AUTOSAR XML (schema 4-0-3)
package /WdgM/CompuMethods
  compu method WdgM_ModeIdTypeValues: 0=WDGM_WDGMMODE0 (WdgMMode0), 1=WDGM_WDGMMODE1 (WdgMMode1)
  compu method WdgM_SupervisedEntityIdTypeValues: 300=WDGM_SE_INIT (SE_Init), 400=WDGM_SE_WDGMTEST (SE_WdgMTest), 500=WDGM_SE_WDGMELS_01 (SE_WdgMELS_01), 600=WDGM_SE_WDGMELS_02 (SE_WdgMELS_02)
  compu method WdgM_CheckpointIdTypeValues: 0=WDGM_SE_INIT_CP_INIT_AS0 (SE_Init_CP_Init_AS0), 1=WDGM_SE_INIT_CP_INIT_ILS_0 (SE_Init_CP_Init_ILS_0), 2=WDGM_SE_INIT_CP_INIT_ILS_1 (SE_Init_CP_Init_ILS_1), 0=WDGM_SE_WDGMTEST_CP_WDGMTEST_AS0 (SE_WdgMTest_CP_WdgMTest_AS0), 1=WDGM_SE_WDGMTEST_CP_WDGMTEST_ILS_0 (SE_WdgMTest_CP_WdgMTest_ILS_0), 2=WDGM_SE_WDGMTEST_CP_WDGMTEST_ILS_1 (SE_WdgMTest_CP_WdgMTest_ILS_1), 3=WDGM_SE_WDGMTEST_CP_WDGMTEST_ILS_2 (SE_WdgMTest_CP_WdgMTest_ILS_2), 4=WDGM_SE_WDGMTEST_CP_WDGMTEST_DS0 (SE_WdgMTest_CP_WdgMTest_DS0), 5=WDGM_SE_WDGMTEST_CP_WDGMTEST_DS1 (SE_WdgMTest_CP_WdgMTest_DS1), 0=WDGM_SE_WDGMELS_01_CP_ELS_01_01 (SE_WdgMELS_01_CP_ELS_01_01), 1=WDGM_SE_WDGMELS_01_CP_ELS_01_02 (SE_WdgMELS_01_CP_ELS_01_02), 2=WDGM_SE_WDGMELS_01_CP_ELS_01_ILS_01 (SE_WdgMELS_01_CP_ELS_01_ILS_01), 3=WDGM_SE_WDGMELS_01_CP_ELS_01_ILS_02 (SE_WdgMELS_01_CP_ELS_01_ILS_02), 0=WDGM_SE_WDGMELS_02_CP_ELS_02_01 (SE_WdgMELS_02_CP_ELS_02_01), 1=WDGM_SE_WDGMELS_02_CP_ELS_02_02 (SE_WdgMELS_02_CP_ELS_02_02), 2=WDGM_SE_WDGMELS_02_CP_ELS_02_ILS_01 (SE_WdgMELS_02_CP_ELS_02_ILS_01), 3=WDGM_SE_WDGMELS_02_CP_ELS_02_ILS_02 (SE_WdgMELS_02_CP_ELS_02_ILS_02)
package /WdgM/ServiceSwComponentTypes
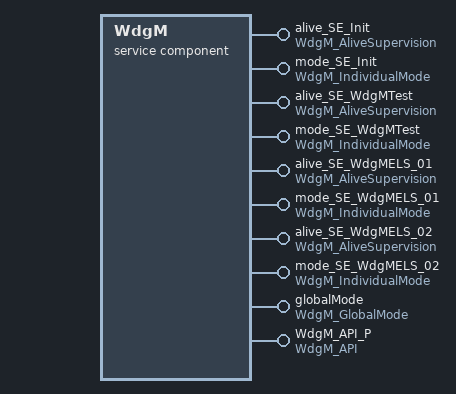
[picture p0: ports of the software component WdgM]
  service sw component type WdgM
    10 x provide port:
      alive_SE_Init: provided-com-specs=[{operation=CheckpointReached, queue-length=1}, {operation=UpdateAliveCounter, queue-length=1}], provided-interface=WdgM_AliveSupervision  # alive_SE_Init is a P Port for supervised entity 'SE_Init'
      mode_SE_Init: mode-switch-sender-com-spec{enhanced-mode-api=false, mode-group=currentMode, queue-length=1}, provided-interface=WdgM_IndividualMode  # mode_SE_Init is a P Port for supervised entity 'SE_Init'
      alive_SE_WdgMTest: provided-com-specs=[{operation=CheckpointReached, queue-length=1}, {operation=UpdateAliveCounter, queue-length=1}], provided-interface=WdgM_AliveSupervision  # alive_SE_WdgMTest is a P Port for supervised entity 'SE_WdgMTest'
      mode_SE_WdgMTest: mode-switch-sender-com-spec{enhanced-mode-api=false, mode-group=currentMode, queue-length=1}, provided-interface=WdgM_IndividualMode  # mode_SE_WdgMTest is a P Port for supervised entity 'SE_WdgMTest'
      alive_SE_WdgMELS_01: provided-com-specs=[{operation=CheckpointReached, queue-length=1}, {operation=UpdateAliveCounter, queue-length=1}], provided-interface=WdgM_AliveSupervision  # alive_SE_WdgMELS_01 is a P Port for supervised entity 'SE_WdgMELS_01'
      mode_SE_WdgMELS_01: mode-switch-sender-com-spec{enhanced-mode-api=false, mode-group=currentMode, queue-length=1}, provided-interface=WdgM_IndividualMode  # mode_SE_WdgMELS_01 is a P Port for supervised entity 'SE_WdgMELS_01'
      alive_SE_WdgMELS_02: provided-com-specs=[{operation=CheckpointReached, queue-length=1}, {operation=UpdateAliveCounter, queue-length=1}], provided-interface=WdgM_AliveSupervision  # alive_SE_WdgMELS_02 is a P Port for supervised entity 'SE_WdgMELS_02'
      mode_SE_WdgMELS_02: mode-switch-sender-com-spec{enhanced-mode-api=false, mode-group=currentMode, queue-length=1}, provided-interface=WdgM_IndividualMode  # mode_SE_WdgMELS_02 is a P Port for supervised entity 'SE_WdgMELS_02'
      globalMode: mode-switch-sender-com-spec{enhanced-mode-api=false, mode-group=currentMode, queue-length=1}, provided-interface=WdgM_GlobalMode  # short_name is a P Port for supervised entity 'sesn'
      WdgM_API_P: provided-interface=WdgM_API  # short_name is a P Port for supervised entity 'sesn'
        provided-com-specs:
          operation=SetMode, queue-length=1
          operation=GetMode, queue-length=1
          operation=GetLocalStatus, queue-length=1
          operation=GetGlobalStatus, queue-length=1
          operation=PerformReset, queue-length=1
          operation=GetFirstExpiredSEID, queue-length=1
    behavior WdgMInternalBehavior: data-type-mapping=WdgM_Mode, handle-termination-and-restart=NO-SUPPORT
      14 x operation invoked event:
        OperationInvokedEvent_alive_SE_Init_CheckpointReached: start-on-event=CheckpointReached, operation=alive_SE_Init.CheckpointReached
        OperationInvokedEvent_alive_SE_Init_UpdateAliveCounter: start-on-event=UpdateAliveCounter, operation=alive_SE_Init.UpdateAliveCounter
        OperationInvokedEvent_alive_SE_WdgMTest_CheckpointReached: start-on-event=CheckpointReached, operation=alive_SE_WdgMTest.CheckpointReached
        OperationInvokedEvent_alive_SE_WdgMTest_UpdateAliveCounter: start-on-event=UpdateAliveCounter, operation=alive_SE_WdgMTest.UpdateAliveCounter
        OperationInvokedEvent_alive_SE_WdgMELS_01_CheckpointReached: start-on-event=CheckpointReached, operation=alive_SE_WdgMELS_01.CheckpointReached
        OperationInvokedEvent_alive_SE_WdgMELS_01_UpdateAliveCounter: start-on-event=UpdateAliveCounter, operation=alive_SE_WdgMELS_01.UpdateAliveCounter
        OperationInvokedEvent_alive_SE_WdgMELS_02_CheckpointReached: start-on-event=CheckpointReached, operation=alive_SE_WdgMELS_02.CheckpointReached
        OperationInvokedEvent_alive_SE_WdgMELS_02_UpdateAliveCounter: start-on-event=UpdateAliveCounter, operation=alive_SE_WdgMELS_02.UpdateAliveCounter
        OperationInvokedEvent_SetMode: start-on-event=SetMode, operation=WdgM_API_P.SetMode
        OperationInvokedEvent_GetMode: start-on-event=GetMode, operation=WdgM_API_P.GetMode
        OperationInvokedEvent_GetLocalStatus: start-on-event=GetLocalStatus, operation=WdgM_API_P.GetLocalStatus
        OperationInvokedEvent_GetGlobalStatus: start-on-event=GetGlobalStatus, operation=WdgM_API_P.GetGlobalStatus
        OperationInvokedEvent_PerformReset: start-on-event=PerformReset, operation=WdgM_API_P.PerformReset
        OperationInvokedEvent_GetFirstExpiredSEID: start-on-event=GetFirstExpiredSEID, operation=WdgM_API_P.GetFirstExpiredSEID
      port-api-options:
        {enable-take-address=false, indirect-api=false, port-defined-argument-value{value=300, value-type=WdgM_SupervisedEntityIdType}, port=alive_SE_Init}
        {enable-take-address=false, indirect-api=false, port-defined-argument-value{value=alive_SE_WdgMTest_SEID:400, value-type=WdgM_SupervisedEntityIdType}, port=alive_SE_WdgMTest}
        {enable-take-address=false, indirect-api=false, port-defined-argument-value{value=alive_SE_WdgMELS_01_SEID:500, value-type=WdgM_SupervisedEntityIdType}, port=alive_SE_WdgMELS_01}
        {enable-take-address=false, indirect-api=false, port-defined-argument-value{value=alive_SE_WdgMELS_02_SEID:600, value-type=WdgM_SupervisedEntityIdType}, port=alive_SE_WdgMELS_02}
      9 x runnable:
        SetMode: arguments=[symbol=ddMode, symbol=usCallerID], symbol=WdgM_SetMode
        GetMode: runnable-entity-argument=symbol=pMode, can-be-invoked-concurrently=true, symbol=WdgM_GetMode
        CheckpointReached: arguments=[symbol=ddSEID, symbol=ddCheckpointID], can-be-invoked-concurrently=true, symbol=WdgM_CheckpointReached
        UpdateAliveCounter: runnable-entity-argument=symbol=ddSEID, can-be-invoked-concurrently=true, symbol=WdgM_UpdateAliveCounter
        GetLocalStatus: arguments=[symbol=ddSEID, symbol=pStatus], can-be-invoked-concurrently=true, symbol=WdgM_GetLocalStatus
        GetGlobalStatus: runnable-entity-argument=symbol=pStatus, can-be-invoked-concurrently=true, symbol=WdgM_GetGlobalStatus
        PerformReset: symbol=WdgM_PerformReset
        GetFirstExpiredSEID: runnable-entity-argument=symbol=pSEID, can-be-invoked-concurrently=true, symbol=WdgM_GetFirstExpiredSEID
        MainFunction: symbol=WdgM_MainFunction
          mode-access-points:
            mode_SE_Init.currentMode
            mode_SE_WdgMTest.currentMode
            mode_SE_WdgMELS_01.currentMode
            mode_SE_WdgMELS_02.currentMode
            globalMode.currentMode
          5 x mode switch point:
            ModeSwitchPoint_mode_SE_Init: mode-group=mode_SE_Init.currentMode
            ModeSwitchPoint_mode_SE_WdgMTest: mode-group=mode_SE_WdgMTest.currentMode
            ModeSwitchPoint_mode_SE_WdgMELS_01: mode-group=mode_SE_WdgMELS_01.currentMode
            ModeSwitchPoint_mode_SE_WdgMELS_02: mode-group=mode_SE_WdgMELS_02.currentMode
            ModeSwitchPoint_globalmode: mode-group=globalMode.currentMode
  swc bsw mapping SwcBswMapping_WdgM: bsw-behavior=BswInternalBehavior_WdgM, swc-behavior=WdgMInternalBehavior
    runnable-mappings:
      bsw-entity=BswSE_WdgM_MainFunction, swc-runnable=MainFunction
      bsw-entity=BswCE_WdgM_CheckpointReached, swc-runnable=CheckpointReached
      bsw-entity=BswCE_WdgM_UpdateAliveCounter, swc-runnable=UpdateAliveCounter
  swc implementation SwcImplementation_WdgM: swc-bsw-mapping=SwcBswMapping_WdgM, behavior=WdgMInternalBehavior
